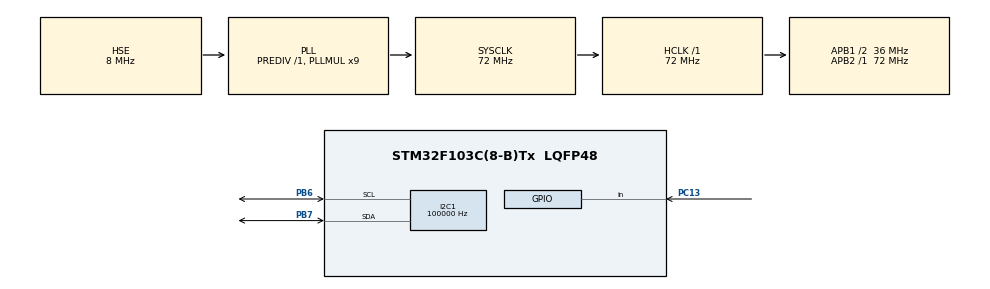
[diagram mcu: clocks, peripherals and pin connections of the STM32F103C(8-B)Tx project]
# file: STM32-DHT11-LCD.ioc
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Mcu.Family=STM32F1
RCC.PLLSourceVirtual=RCC_PLLSOURCE_HSE
PD1-OSC_OUT.Mode=HSE-External-Oscillator
PC13-TAMPER-RTC.Signal=GPIO_Input
PD0-OSC_IN.Signal=RCC_OSC_IN
RCC.APB1CLKDivider=RCC_HCLK_DIV2
RCC.SYSCLKSource=RCC_SYSCLKSOURCE_PLLCLK
ProjectManager.StackSize=0x400
PD1-OSC_OUT.Signal=RCC_OSC_OUT
PA13.Signal=SYS_JTMS-SWDIO
TIM1.Prescaler=72-1
ProjectManager.TargetToolchain=STM32CubeIDE
I2C1.ClockSpeed=100000
RCC.HCLKFreq_Value=72000000
RCC.APB2TimFreq_Value=72000000
PB6.Signal=I2C1_SCL
PB6.Mode=I2C
RCC.USBFreq_Value=72000000
RCC.AHBFreq_Value=72000000
PD0-OSC_IN.Mode=HSE-External-Oscillator
board=custom
RCC.PLLMUL=RCC_PLL_MUL9
RCC.APB2Freq_Value=72000000
PA14.Mode=Serial_Wire
PB7.Signal=I2C1_SDA
PA13.Mode=Serial_Wire
Mcu.Name=STM32F103C(8-B)Tx
VP_TIM1_VS_ClockSourceINT.Mode=Internal
RCC.SYSCLKFreq_VALUE=72000000
Mcu.Package=LQFP48
PC13-TAMPER-RTC.GPIO_PuPd=GPIO_PULLUP
PB7.Mode=I2C
PA14.Signal=SYS_JTCK-SWCLK
ProjectManager.HeapSize=0x200
NVIC.PriorityGroup=NVIC_PRIORITYGROUP_4
RCC.APB1TimFreq_Value=72000000
TIM1.Period=0xffff-1
RCC.APB1Freq_Value=36000000

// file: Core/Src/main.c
/* USER CODE BEGIN Header */
/**
  ******************************************************************************
  * @file           : main.c
  * @brief          : Main program body
  ******************************************************************************
  * @attention
  *
  * <h2><center>&copy; Copyright (c) 2021 STMicroelectronics.
  * All rights reserved.</center></h2>
  *
  * This software component is licensed by ST under BSD 3-Clause license,
  * the "License"; You may not use this file except in compliance with the
  * License. You may obtain a copy of the License at:
  *                        opensource.org/licenses/BSD-3-Clause
  *
  ******************************************************************************
  */
/* USER CODE END Header */
#include "main.h"
#include "i2c-lcd.h"
#include "stdio.h"

I2C_HandleTypeDef hi2c1;

TIM_HandleTypeDef htim1;

void SystemClock_Config(void);
static void MX_GPIO_Init(void);
static void MX_I2C1_Init(void);
static void MX_TIM1_Init(void);
/* USER CODE BEGIN PFP */
static void DHT11_GpioInput(void);
static void DHT11_GpioOutput(void);
/* USER CODE END PFP */

/* USER CODE BEGIN 0 */
/*********************************DHT11****************************************/
uint8_t DHT11_Temperature = 0;
uint8_t DHT11_Humidity = 0;
uint8_t hByte1, hByte2, tByte1, tByte2, presence;
uint8_t checksum;
/**
  * @brief GPIO Initialization Function
  * @param None
  * @retval None
  */
static void DHT11_GpioInput(void)
{
  GPIO_InitTypeDef GPIO_InitStruct = {0};
  /*Configure GPIO pin : PC13 */
  GPIO_InitStruct.Pin = GPIO_PIN_13;
  GPIO_InitStruct.Mode = GPIO_MODE_INPUT;
  GPIO_InitStruct.Pull = GPIO_PULLUP;
  HAL_GPIO_Init(GPIOC, &GPIO_InitStruct);
}

/**
  * @brief GPIO Initialization Function
  * @param None
  * @retval None
  */
static void DHT11_GpioOutput(void)
{
  GPIO_InitTypeDef GPIO_InitStruct = {0};
  /*Configure GPIO pin Output Level */
  HAL_GPIO_WritePin(GPIOC, GPIO_PIN_13, GPIO_PIN_RESET);

  /*Configure GPIO pin : PC13 */
  GPIO_InitStruct.Pin = GPIO_PIN_13;
  GPIO_InitStruct.Mode = GPIO_MODE_OUTPUT_PP;
  GPIO_InitStruct.Pull = GPIO_NOPULL;
  GPIO_InitStruct.Speed = GPIO_SPEED_FREQ_HIGH;
  HAL_GPIO_Init(GPIOC, &GPIO_InitStruct);

  /*Configure GPIO pin : PC14 */
  // GPIO_InitStruct.Pin = GPIO_PIN_14;
  // GPIO_InitStruct.Mode = GPIO_MODE_OUTPUT_PP;
  // GPIO_InitStruct.Pull = GPIO_NOPULL;
  // GPIO_InitStruct.Speed = GPIO_SPEED_FREQ_HIGH;
  // HAL_GPIO_Init(GPIOC, &GPIO_InitStruct);
}

// hàm delay us trong quá trình đọc dữ liệu từ dht11
void TIM1_DelayUs(uint16_t us)
{
  __HAL_TIM_SET_COUNTER(&htim1, 0);
  while ((uint16_t)__HAL_TIM_GET_COUNTER(&htim1) < us)
    ;
}

// gửi tín hiệu bắt đầu truyền dữ liệu cho dht11
void DHT11_SendStart(void)
{
  DHT11_GpioOutput();
  HAL_GPIO_WritePin(GPIOC, GPIO_PIN_13, GPIO_PIN_RESET);
  HAL_Delay(18);
  HAL_GPIO_WritePin(GPIOC, GPIO_PIN_13, GPIO_PIN_SET);
  TIM1_DelayUs(20);
  DHT11_GpioInput();
}

// hàm kiểm tra phản hồi của dht11
uint8_t DHT11_CheckRespone(void)
{
  uint8_t respone = 0;
  TIM1_DelayUs(40);
  if (!HAL_GPIO_ReadPin(GPIOC, GPIO_PIN_13))
  {
    TIM1_DelayUs(80);
    if ((HAL_GPIO_ReadPin(GPIOC, GPIO_PIN_13)))
    {
      respone = 1;
    }
    else
    {
      respone = -1;
    }
  }
  while (HAL_GPIO_ReadPin(GPIOC, GPIO_PIN_13))
    ;
  return respone;
}

// đọc 1 byte dữ liệu từ dht11
uint8_t DHT11_ReadByte(void)
{
  uint8_t ret = 0, i;
  for (i = 0; i < 8; i++)
  {
    while (!HAL_GPIO_ReadPin(GPIOC, GPIO_PIN_13))
      ;
    TIM1_DelayUs(40);
    if (!HAL_GPIO_ReadPin(GPIOC, GPIO_PIN_13))
    {
      ret &= ~(1 << (7 - i));
    }
    else
    {
      ret |= (1 << (7 - i));
    }
    while ((HAL_GPIO_ReadPin(GPIOC, GPIO_PIN_13)))
      ;
  }
  return ret;
}

// đọc dữ liệu từ dht11 và chuyển đổi thành giá trị nhiệt độ và độ ẩm
void DHT11_ReadSensor(void)
{
  DHT11_SendStart();
  presence = DHT11_CheckRespone();
  hByte1 = DHT11_ReadByte();
  hByte2 = DHT11_ReadByte();
  tByte1 = DHT11_ReadByte();
  tByte2 = DHT11_ReadByte();
  checksum = DHT11_ReadByte();
  DHT11_Temperature = tByte1;
  DHT11_Humidity = hByte1;
}
/*********************************DHT11****************************************/

/*********************************LCD****************************************/
// hiển thị nhiệt độ và độ ẩm lên lcd
void LCD_Display(void)
{
  char tempString[4];
  lcd_clear_display();
  lcd_goto_XY(0, 0);
  lcd_send_string("Temp: ");
  sprintf(tempString, "%u", DHT11_Temperature);
  lcd_send_string(tempString);
  lcd_send_string(" oC");
  lcd_goto_XY(1,0);
  lcd_send_string("Humid: ");
  sprintf(tempString, "%u", DHT11_Humidity);
  lcd_send_string(tempString);
  lcd_send_string(" %");
}
/*********************************LCD****************************************/
/* USER CODE END 0 */

int main(void)
{

  /* MCU Configuration--------------------------------------------------------*/

  /* Reset of all peripherals, Initializes the Flash interface and the Systick. */
  HAL_Init();

  /* Configure the system clock */
  SystemClock_Config();

  /* Initialize all configured peripherals */
  MX_GPIO_Init();
  MX_I2C1_Init();
  MX_TIM1_Init();
  /* USER CODE BEGIN 2 */
  HAL_TIM_Base_Start(&htim1);
  HAL_Delay(1000);
  lcd_init();
  /* USER CODE END 2 */

  /* Infinite loop */
  /* USER CODE BEGIN WHILE */
  while (1)
  {
    DHT11_ReadSensor();
    LCD_Display();
    HAL_Delay(2000);
    /* USER CODE END WHILE */

  }
}

void SystemClock_Config(void)
{
  RCC_OscInitTypeDef RCC_OscInitStruct = {0};
  RCC_ClkInitTypeDef RCC_ClkInitStruct = {0};

  /** Initializes the RCC Oscillators according to the specified parameters
  * in the RCC_OscInitTypeDef structure.
  */
  RCC_OscInitStruct.OscillatorType = RCC_OSCILLATORTYPE_HSE;
  RCC_OscInitStruct.HSEState = RCC_HSE_ON;
  RCC_OscInitStruct.HSEPredivValue = RCC_HSE_PREDIV_DIV1;
  RCC_OscInitStruct.HSIState = RCC_HSI_ON;
  RCC_OscInitStruct.PLL.PLLState = RCC_PLL_ON;
  RCC_OscInitStruct.PLL.PLLSource = RCC_PLLSOURCE_HSE;
  RCC_OscInitStruct.PLL.PLLMUL = RCC_PLL_MUL9;
  if (HAL_RCC_OscConfig(&RCC_OscInitStruct) != HAL_OK)
  {
    Error_Handler();
  }
  /** Initializes the CPU, AHB and APB buses clocks
  */
  RCC_ClkInitStruct.ClockType = RCC_CLOCKTYPE_HCLK | RCC_CLOCKTYPE_SYSCLK | RCC_CLOCKTYPE_PCLK1 | RCC_CLOCKTYPE_PCLK2;
  RCC_ClkInitStruct.SYSCLKSource = RCC_SYSCLKSOURCE_PLLCLK;
  RCC_ClkInitStruct.AHBCLKDivider = RCC_SYSCLK_DIV1;
  RCC_ClkInitStruct.APB1CLKDivider = RCC_HCLK_DIV2;
  RCC_ClkInitStruct.APB2CLKDivider = RCC_HCLK_DIV1;

  if (HAL_RCC_ClockConfig(&RCC_ClkInitStruct, FLASH_LATENCY_2) != HAL_OK)
  {
    Error_Handler();
  }
}

static void MX_I2C1_Init(void)
{

  hi2c1.Instance = I2C1;
  hi2c1.Init.ClockSpeed = 100000;
  hi2c1.Init.DutyCycle = I2C_DUTYCYCLE_2;
  hi2c1.Init.OwnAddress1 = 0;
  hi2c1.Init.AddressingMode = I2C_ADDRESSINGMODE_7BIT;
  hi2c1.Init.DualAddressMode = I2C_DUALADDRESS_DISABLE;
  hi2c1.Init.OwnAddress2 = 0;
  hi2c1.Init.GeneralCallMode = I2C_GENERALCALL_DISABLE;
  hi2c1.Init.NoStretchMode = I2C_NOSTRETCH_DISABLE;
  if (HAL_I2C_Init(&hi2c1) != HAL_OK)
  {
    Error_Handler();
  }
}

static void MX_TIM1_Init(void)
{

  TIM_ClockConfigTypeDef sClockSourceConfig = {0};
  TIM_MasterConfigTypeDef sMasterConfig = {0};

  htim1.Instance = TIM1;
  htim1.Init.Prescaler = 72 - 1;
  htim1.Init.CounterMode = TIM_COUNTERMODE_UP;
  htim1.Init.Period = 0xffff - 1;
  htim1.Init.ClockDivision = TIM_CLOCKDIVISION_DIV1;
  htim1.Init.RepetitionCounter = 0;
  htim1.Init.AutoReloadPreload = TIM_AUTORELOAD_PRELOAD_DISABLE;
  if (HAL_TIM_Base_Init(&htim1) != HAL_OK)
  {
    Error_Handler();
  }
  sClockSourceConfig.ClockSource = TIM_CLOCKSOURCE_INTERNAL;
  if (HAL_TIM_ConfigClockSource(&htim1, &sClockSourceConfig) != HAL_OK)
  {
    Error_Handler();
  }
  sMasterConfig.MasterOutputTrigger = TIM_TRGO_RESET;
  sMasterConfig.MasterSlaveMode = TIM_MASTERSLAVEMODE_DISABLE;
  if (HAL_TIMEx_MasterConfigSynchronization(&htim1, &sMasterConfig) != HAL_OK)
  {
    Error_Handler();
  }
}

static void MX_GPIO_Init(void)
{
  GPIO_InitTypeDef GPIO_InitStruct = {0};

  /* GPIO Ports Clock Enable */
  __HAL_RCC_GPIOC_CLK_ENABLE();
  __HAL_RCC_GPIOD_CLK_ENABLE();
  __HAL_RCC_GPIOA_CLK_ENABLE();
  __HAL_RCC_GPIOB_CLK_ENABLE();

  /*Configure GPIO pin : PC13 */
  GPIO_InitStruct.Pin = GPIO_PIN_13;
  GPIO_InitStruct.Mode = GPIO_MODE_INPUT;
  GPIO_InitStruct.Pull = GPIO_PULLUP;
  HAL_GPIO_Init(GPIOC, &GPIO_InitStruct);
}

void Error_Handler(void)
{
  __disable_irq();
  while (1)
  {
  }
}

/************************ (C) COPYRIGHT STMicroelectronics *****END OF FILE****/
